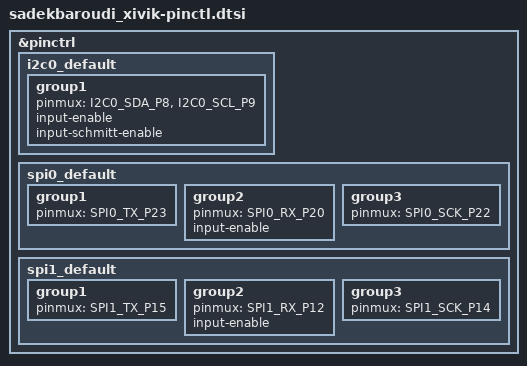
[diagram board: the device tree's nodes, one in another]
/*
 * Copyright (c) 2021, Yonatan Schachter
 * SPDX-License-Identifier: Apache-2.0
 */

#include <dt-bindings/pinctrl/rpi-pico-rp2040-pinctrl.h>

&pinctrl {
	/**
	// generally not supported for now
	// v0.2 only, need to comment out for v0.1
	uart0_default: uart0_default {
		group1 {
			pinmux = <UART0_TX_P4>;
		};
		group2 {
			pinmux = <UART0_RX_P21>;
			input-enable;
		};
	};
	*/

	// vik i2c pinout
	i2c0_default: i2c0_default {
		group1 {
			// v0.1 - need to swap to i2c1 as well
			// pinmux = <I2C1_SDA_P22>, <I2C1_SCL_P23>;
			pinmux = <I2C0_SDA_P8>, <I2C0_SCL_P9>;
			input-enable;
			input-schmitt-enable;
		};
	};

	/** disable for v0.2, can uncomment for v0.1
	// through hole i2c pinout
	// broken in v0.2, used GP5 and GP6, which are on different i2c buses, maybe when PIO support, can re-enable
	i2c1_default: i2c1_default {
		group1 {
			// v0.1
			pinmux = <I2C0_SDA_P4>, pinmux = <I2C0_SCL_P5>;
			// v0.2 - see comment above i2c1_default declaration
			// pinmux = <RP2040_PINMUX(5, RP2_PINCTRL_GPIO_FUNC_I2C)>, <RP2040_PINMUX(6, RP2_PINCTRL_GPIO_FUNC_I2C)>;
			input-enable;
			input-schmitt-enable;
		};
	};
	*/

	// through hole spi pinout
	spi0_default: spi0_default {
		group1 {
			pinmux = <SPI0_TX_P23>;
		};
		group2 {
			pinmux = <SPI0_RX_P20>;
			input-enable;
		};
		group3 {
			pinmux = <SPI0_SCK_P22>;
		};
	};

	// vik spi pinout
	spi1_default: spi1_default {
		group1 {
			pinmux = <SPI1_TX_P15>;
		};
		group2 {
			pinmux = <SPI1_RX_P12>;
			input-enable;
		};
		group3 {
			pinmux = <SPI1_SCK_P14>;
		};
	};

	/**
	// v0.1 - may need PIO driver support
	// see https://docs.zephyrproject.org/apidoc/latest/rpi-pico-rp2040-pinctrl_8h.html
	// through hole spi pinout
	spi1_default: spi1_default {
		group1 {
			pinmux = <SPI1_TX_P24>;
		};
		group2 {
			pinmux = <SPI1_RX_P9>;
			input-enable;
		};
		group3 {
			pinmux = <SPI1_SCK_P8>;
		};
	};
	*/
};
